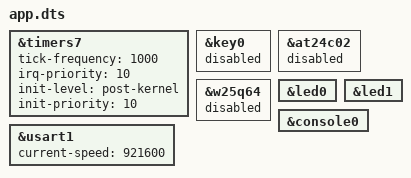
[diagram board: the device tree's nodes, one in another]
/include/ "../../boards/fire-mini-stm32f103/board.dts"

&timers7 {
    tick-frequency = <1000>;
    irq-priority = <10>;
    init-level = "post-kernel";
    init-priority = <10>;
    status = "okay";
};

&key0 {
    status = "disabled";
};

&at24c02 {
    status = "disabled";
};

&w25q64 {
    status = "disabled";
};

&led0 {
    status = "okay";
};

&led1 {
    status = "okay";
};

&console0 {
    status = "okay";
};

&usart1 {
    current-speed = <921600>;
    status = "okay";
};
